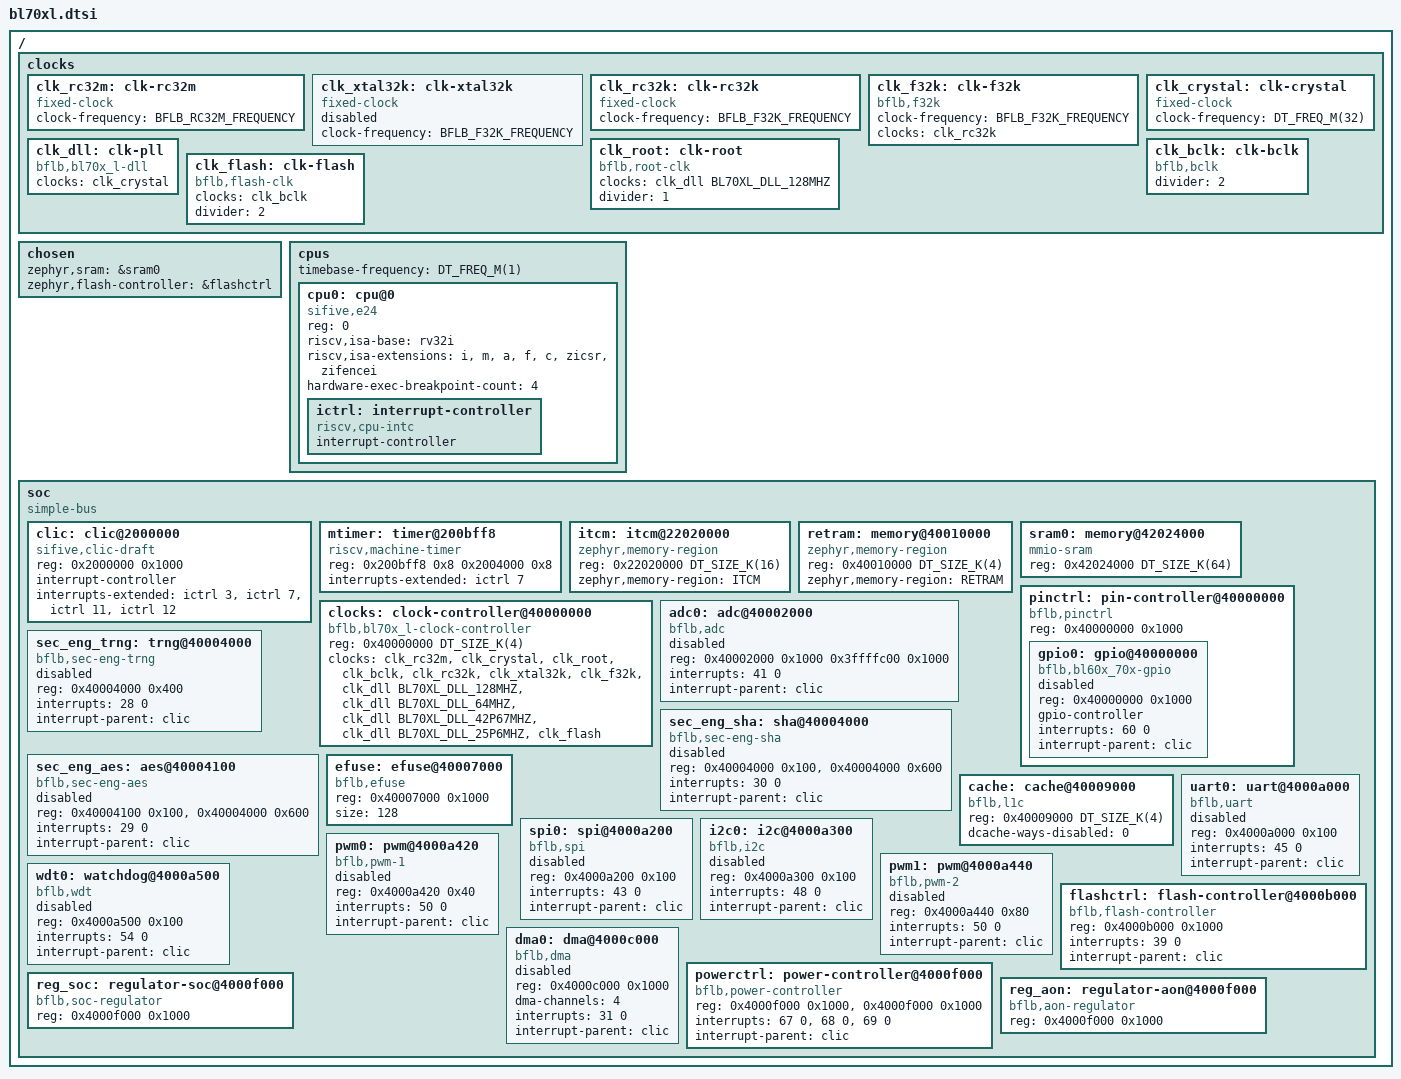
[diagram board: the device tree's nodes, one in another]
/*
 * Copyright The Zephyr Project Contributors
 *
 * SPDX-License-Identifier: Apache-2.0
 */

#include <freq.h>
#include <mem.h>
#include <zephyr/dt-bindings/pinctrl/bflb-common-pinctrl.h>
#include <zephyr/dt-bindings/pinctrl/bl70xl-pinctrl.h>
#include <zephyr/dt-bindings/clock/bflb_bl70xl_clock.h>
#include <zephyr/dt-bindings/gpio/gpio.h>
#include <zephyr/dt-bindings/input/input-event-codes.h>
#include <zephyr/dt-bindings/i2c/i2c.h>
#include <zephyr/dt-bindings/spi/spi.h>
#include <zephyr/dt-bindings/pwm/pwm.h>
#include <zephyr/dt-bindings/adc/adc.h>

/ {
	#address-cells = <1>;
	#size-cells = <1>;

	clocks {
		clk_rc32m: clk-rc32m {
			#clock-cells = <0>;
			compatible = "fixed-clock";
			clock-frequency = <BFLB_RC32M_FREQUENCY>;
		};

		clk_xtal32k: clk-xtal32k {
			#clock-cells = <0>;
			compatible = "fixed-clock";
			clock-frequency = <BFLB_F32K_FREQUENCY>;
			status = "disabled";
		};

		clk_rc32k: clk-rc32k {
			#clock-cells = <0>;
			compatible = "fixed-clock";
			clock-frequency = <BFLB_F32K_FREQUENCY>;
		};

		clk_f32k: clk-f32k {
			#clock-cells = <0>;
			compatible = "bflb,f32k";
			clock-frequency = <BFLB_F32K_FREQUENCY>;
			clocks = <&clk_rc32k>;
		};

		clk_crystal: clk-crystal {
			#clock-cells = <0>;
			compatible = "fixed-clock";
			clock-frequency = <DT_FREQ_M(32)>;
		};

		clk_dll: clk-pll {
			#clock-cells = <1>;
			compatible = "bflb,bl70x_l-dll";
			clocks = <&clk_crystal>;
		};

		clk_root: clk-root {
			#clock-cells = <0>;
			compatible = "bflb,root-clk";
			clocks = <&clk_dll BL70XL_DLL_128MHZ>;
			divider = <1>;
		};

		clk_bclk: clk-bclk {
			#clock-cells = <0>;
			compatible = "bflb,bclk";
			divider = <2>;
		};

		clk_flash: clk-flash {
			#clock-cells = <0>;
			compatible = "bflb,flash-clk";
			clocks = <&clk_bclk>;
			divider = <2>;
		};
	};

	chosen {
		zephyr,sram = &sram0;
		zephyr,flash-controller = &flashctrl;
	};

	cpus {
		#address-cells = <1>;
		#size-cells = <0>;
		timebase-frequency = <DT_FREQ_M(1)>;

		cpu0: cpu@0 {
			device_type = "cpu";
			compatible = "sifive,e24", "riscv";
			reg = <0>;
			riscv,isa-base = "rv32i";
			riscv,isa-extensions = "i", "m", "a", "f", "c", "zicsr", "zifencei";
			hardware-exec-breakpoint-count = <4>;

			ictrl: interrupt-controller {
				#address-cells = <0>;
				#interrupt-cells = <1>;
				compatible = "riscv,cpu-intc";
				interrupt-controller;
			};
		};
	};

	soc {
		compatible = "simple-bus";
		#address-cells = <1>;
		#size-cells = <1>;
		ranges;

		clic: clic@2000000 {
			compatible = "sifive,clic-draft";
			reg = <0x2000000 0x1000>;
			#address-cells = <0>;
			#interrupt-cells = <2>;

			interrupt-controller;
			interrupts-extended = <&ictrl 3 &ictrl 7 &ictrl 11 &ictrl 12>;
			interrupt-names = "msip", /* Machine Software Interrupt */
					  "mtip", /* Machine Timer interrupt    */
					  "meip", /* Machine External Interrupt */
					  "csip"; /* CLIC Software Interrupt    */
		};

		mtimer: timer@200bff8 {
			compatible = "riscv,machine-timer";
			reg = <0x200bff8 0x8 0x2004000 0x8>;
			reg-names = "mtime", "mtimecmp";
			interrupts-extended = <&ictrl 7>;
		};

		itcm: itcm@22020000 {
			compatible = "zephyr,memory-region", "mmio-sram";
			reg = <0x22020000 DT_SIZE_K(16)>;
			zephyr,memory-region = "ITCM";
		};

		retram: memory@40010000 {
			compatible = "zephyr,memory-region", "mmio-sram";
			reg = <0x40010000 DT_SIZE_K(4)>;
			zephyr,memory-region = "RETRAM";
		};

		sram0: memory@42024000 {
			compatible = "mmio-sram";
			reg = <0x42024000 DT_SIZE_K(64)>;
		};

		pinctrl: pin-controller@40000000 {
			compatible = "bflb,pinctrl";
			reg = <0x40000000 0x1000>;
			ranges = <0x40000000 0x40000000 0x1000>;
			#address-cells = <1>;
			#size-cells = <1>;

			gpio0: gpio@40000000 {
				compatible = "bflb,bl60x_70x-gpio";
				reg = <0x40000000 0x1000>;
				#gpio-cells = <2>;
				status = "disabled";

				gpio-controller;
				interrupts = <60 0>;
				interrupt-parent = <&clic>;
			};
		};

		clocks: clock-controller@40000000 {
			compatible = "bflb,bl70x_l-clock-controller", "bflb,clock-controller";
			reg = <0x40000000 DT_SIZE_K(4)>;
			#clock-cells = <1>;
			clocks = <&clk_rc32m>, <&clk_crystal>, <&clk_root>, <&clk_bclk>,
				 <&clk_rc32k>, <&clk_xtal32k>, <&clk_f32k>,
				 <&clk_dll BL70XL_DLL_128MHZ>, <&clk_dll BL70XL_DLL_64MHZ>,
				 <&clk_dll BL70XL_DLL_42P67MHZ>, <&clk_dll BL70XL_DLL_25P6MHZ>,
				 <&clk_flash>;
			clock-names = "rc32m", "crystal", "root", "bclk",
				      "rc32k", "xtal32k", "f32k",
				      "dll_128", "dll_64",
				      "dll_42", "dll_25",
				      "flash";
		};

		adc0: adc@40002000 {
			compatible = "bflb,adc";
			reg = <0x40002000 0x1000 0x3ffffc00 0x1000>;
			#io-channel-cells = <1>;
			#address-cells = <1>;
			#size-cells = <0>;
			status = "disabled";

			interrupts = <41 0>;
			interrupt-parent = <&clic>;
		};

		sec_eng_trng: trng@40004000 {
			compatible = "bflb,sec-eng-trng";
			reg = <0x40004000 0x400>;
			interrupts = <28 0>;
			interrupt-parent = <&clic>;
			status = "disabled";
		};

		sec_eng_sha: sha@40004000 {
			compatible = "bflb,sec-eng-sha";
			reg = <0x40004000 0x100>, <0x40004000 0x600>;
			reg-names = "sha", "sec_eng";
			interrupts = <30 0>;
			interrupt-parent = <&clic>;
			status = "disabled";
		};

		sec_eng_aes: aes@40004100 {
			compatible = "bflb,sec-eng-aes";
			reg = <0x40004100 0x100>, <0x40004000 0x600>;
			reg-names = "aes", "sec_eng";
			interrupts = <29 0>;
			interrupt-parent = <&clic>;
			status = "disabled";
		};

		efuse: efuse@40007000 {
			compatible = "bflb,efuse";
			reg = <0x40007000 0x1000>;
			size = <128>;
		};

		cache: cache@40009000 {
			compatible = "bflb,l1c";
			reg = <0x40009000 DT_SIZE_K(4)>;
			dcache-ways-disabled = <0>;
		};

		uart0: uart@4000a000 {
			compatible = "bflb,uart";
			reg = <0x4000a000 0x100>;
			interrupts = <45 0>;
			interrupt-parent = <&clic>;
			status = "disabled";
		};

		spi0: spi@4000a200 {
			compatible = "bflb,spi";
			reg = <0x4000a200 0x100>;
			#address-cells = <1>;
			#size-cells = <0>;
			status = "disabled";

			interrupts = <43 0>;
			interrupt-parent = <&clic>;
		};

		i2c0: i2c@4000a300 {
			compatible = "bflb,i2c";
			reg = <0x4000a300 0x100>;
			#address-cells = <1>;
			#size-cells = <0>;
			status = "disabled";

			interrupts = <48 0>;
			interrupt-parent = <&clic>;
		};

		pwm0: pwm@4000a420 {
			compatible = "bflb,pwm-1";
			reg = <0x4000a420 0x40>;
			#pwm-cells = <3>;
			status = "disabled";

			interrupts = <50 0>;
			interrupt-parent = <&clic>;
		};

		pwm1: pwm@4000a440 {
			compatible = "bflb,pwm-2";
			reg = <0x4000a440 0x80>;
			#pwm-cells = <3>;
			status = "disabled";

			interrupts = <50 0>;
			interrupt-parent = <&clic>;
		};

		wdt0: watchdog@4000a500 {
			compatible = "bflb,wdt";
			reg = <0x4000a500 0x100>;
			status = "disabled";

			interrupts = <54 0>;
			interrupt-parent = <&clic>;
		};

		flashctrl: flash-controller@4000b000 {
			compatible = "bflb,flash-controller";
			reg = <0x4000b000 0x1000>;
			#address-cells = <1>;
			#size-cells = <1>;

			interrupts = <39 0>;
			interrupt-parent = <&clic>;
		};

		dma0: dma@4000c000 {
			compatible = "bflb,dma";
			reg = <0x4000c000 0x1000>;
			#dma-cells = <2>;
			dma-channels = <4>;
			status = "disabled";

			interrupts = <31 0>;
			interrupt-parent = <&clic>;
		};

		powerctrl: power-controller@4000f000 {
			compatible = "bflb,power-controller";
			reg = <0x4000f000 0x1000>, <0x4000f000 0x1000>;
			reg-names = "hbn", "aon";

			interrupts = <67 0>, <68 0>, <69 0>;
			interrupt-parent = <&clic>;
			interrupt-names = "hbn0", "hbn1", "bor";
		};

		reg_soc: regulator-soc@4000f000 {
			compatible = "bflb,soc-regulator";
			reg = <0x4000f000 0x1000>;
		};

		reg_aon: regulator-aon@4000f000 {
			compatible = "bflb,aon-regulator";
			reg = <0x4000f000 0x1000>;
		};
	};
};
